# GD32EPRTxxA register map
File version: 1.0
CPU: CM33 r0p4, little endian, MPU, FPU, 4 interrupt priority bits
Registers are 32-bit, read-write, reset 0x0 unless marked. A register's access mark holds for its fields unless they carry their own. Offsets are from the block's base; [hi:lo] are bit positions; {n}, {i} and the like mark numbered series.

## DBG — Debug support
Base 0xE0044000
0x00 ID ro — ID code register
  [31:0] ID_CODE — DBG ID code register
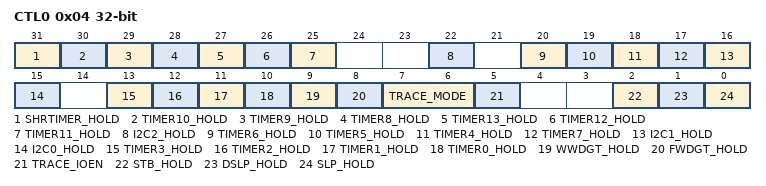
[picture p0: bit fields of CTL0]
0x04 CTL0 — Control register 0
  [31] SHRTIMER_HOLD — SHRTIMER hold bit
  [30] TIMER10_HOLD — TIMER 10 hold bit
  [29] TIMER9_HOLD — TIMER 9 hold bit
  [28] TIMER8_HOLD — TIMER 8 hold bit
  [27] TIMER13_HOLD — TIMER 13 hold bit
  [26] TIMER12_HOLD — TIMER 12 hold bit
  [25] TIMER11_HOLD — TIMER 11 hold bit
  [22] I2C2_HOLD — I2C2 hold bit
  [20] TIMER6_HOLD — TIMER 6 hold bit
  [19] TIMER5_HOLD — TIMER 5 hold bit
  [18] TIMER4_HOLD
  [17] TIMER7_HOLD
  [16] I2C1_HOLD — I2C1 hold bit
  [15] I2C0_HOLD — I2C0 hold bit
  [13] TIMER3_HOLD — TIMER 23 hold bit
  [12] TIMER2_HOLD — TIMER 2 hold bit
  [11] TIMER1_HOLD — TIMER 1 hold bit
  [10] TIMER0_HOLD — TIMER 0 hold bit
  [9] WWDGT_HOLD — WWDGT hold bit
  [8] FWDGT_HOLD — FWDGT hold bit
  [7:6] TRACE_MODE — Trace pin allocation mode
  [5] TRACE_IOEN — Trace pin allocation enable
  [2] STB_HOLD — Standby mode hold register
  [1] DSLP_HOLD — Deep-sleep mode hold register
  [0] SLP_HOLD — Sleep mode hold register

## DMA0 — DMA controller
Base 0x40020000
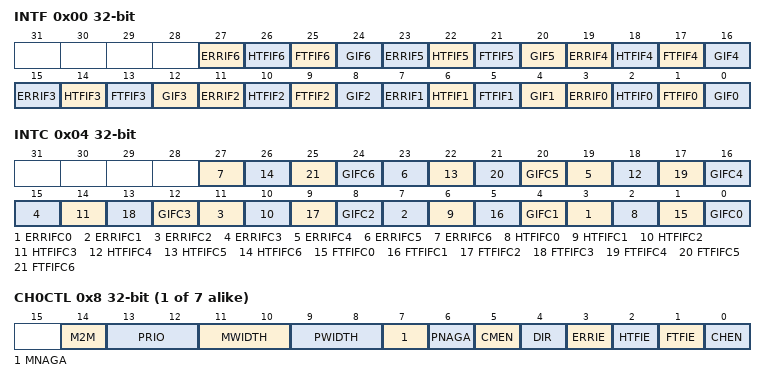
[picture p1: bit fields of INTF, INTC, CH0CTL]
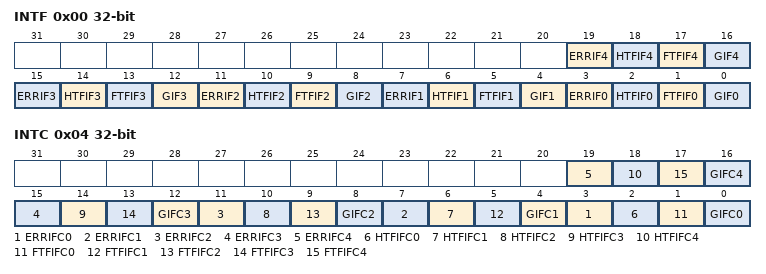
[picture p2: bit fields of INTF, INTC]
0x00 INTF ro — Interrupt flag register
  [4n+3] ERRIF{n} (n=0..6) — Error flag of channel {n}
  [4n+2] HTFIF{n} (n=0..6) — Half transfer finish flag of channel {n}
  [4n+1] FTFIF{n} (n=0..6) — Full Transfer finish flag of channe {n}
  [4n] GIF{n} (n=0..6) — Global interrupt flag of channel {n}
0x04 INTC wo — Interrupt flag clear register
  [4n+3] ERRIFC{n} (n=0..6) — Clear bit for error flag of channel {n}
  [4n+2] HTFIFC{n} (n=0..6) — Clear bit for half transfer finish flag of channel {n}
  [4n+1] FTFIFC{n} (n=0..6) — Clear bit for full transfer finish flag of channel {n}
  [4n] GIFC{n} (n=0..6) — Clear global interrupt flag of channel {n}
{0x8+0x14*i} CH{i}CTL (i=0..6) — Channel {i} control register
  [14] M2M — Memory to Memory Mode
  [13:12] PRIO — Priority level
  [11:10] MWIDTH — Transfer data size of memory
  [9:8] PWIDTH — Transfer data size of peripheral
  [7] MNAGA — Next address generation algorithm of memory
  [6] PNAGA — Next address generation algorithm of peripheral
  [5] CMEN — Circular mode enable
  [4] DIR — Transfer direction
  [3] ERRIE — Enable bit for channel error interrupt
  [2] HTFIE — Enable bit for channel half transfer finish interrupt
  [1] FTFIE — Enable bit for channel full transfer finish interrupt
  [0] CHEN — Channel enable
{0xC+0x14*i} CH{i}CNT (i=0..6) — Channel {i} counter register
  [15:0] CNT — Transfer counter
{0x10+0x14*i} CH{i}PADDR (i=0..6) — Channel {i} peripheral base address register
  [31:0] PADDR — Peripheral base address
{0x14+0x14*i} CH{i}MADDR (i=0..6) — Channel {i} memory base address register
  [31:0] MADDR — Memory base address

## DMA1 — DMA controller
Base 0x40020400
Registers as DMA0, without CH5CTL, CH5CNT, CH5PADDR, CH5MADDR, CH6CTL, CH6CNT, CH6PADDR, CH6MADDR; these are added or differ:
0x00 INTF ro — Interrupt flag register
  [4n+3] ERRIF{n} (n=0..4) — Error flag of channel {n}
  [4n+2] HTFIF{n} (n=0..4) — Half transfer finish flag of channel {n}
  [4n+1] FTFIF{n} (n=0..4) — Full Transfer finish flag of channe {n}
  [4n] GIF{n} (n=0..4) — Global interrupt flag of channel {n}
0x04 INTC wo — Interrupt flag clear register
  [4n+3] ERRIFC{n} (n=0..4) — Clear bit for error flag of channel {n}
  [4n+2] HTFIFC{n} (n=0..4) — Clear bit for half transfer finish flag of channel {n}
  [4n+1] FTFIFC{n} (n=0..4) — Clear bit for full transfer finish flag of channel {n}
  [4n] GIFC{n} (n=0..4) — Clear global interrupt flag of channel {n}

## ENET_MAC_FCTH — MAC flow control threshold register
Base 0x40029080
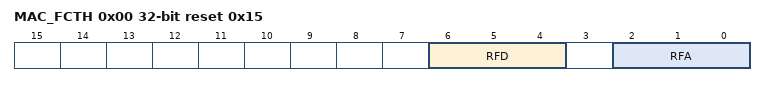
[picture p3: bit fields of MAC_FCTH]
0x00 MAC_FCTH reset 0x15 — Ethernet MAC flow control threshold register
  [6:4] RFD — Threshold of deactive flow control
  [2:0] RFA — Threshold of active flow control
